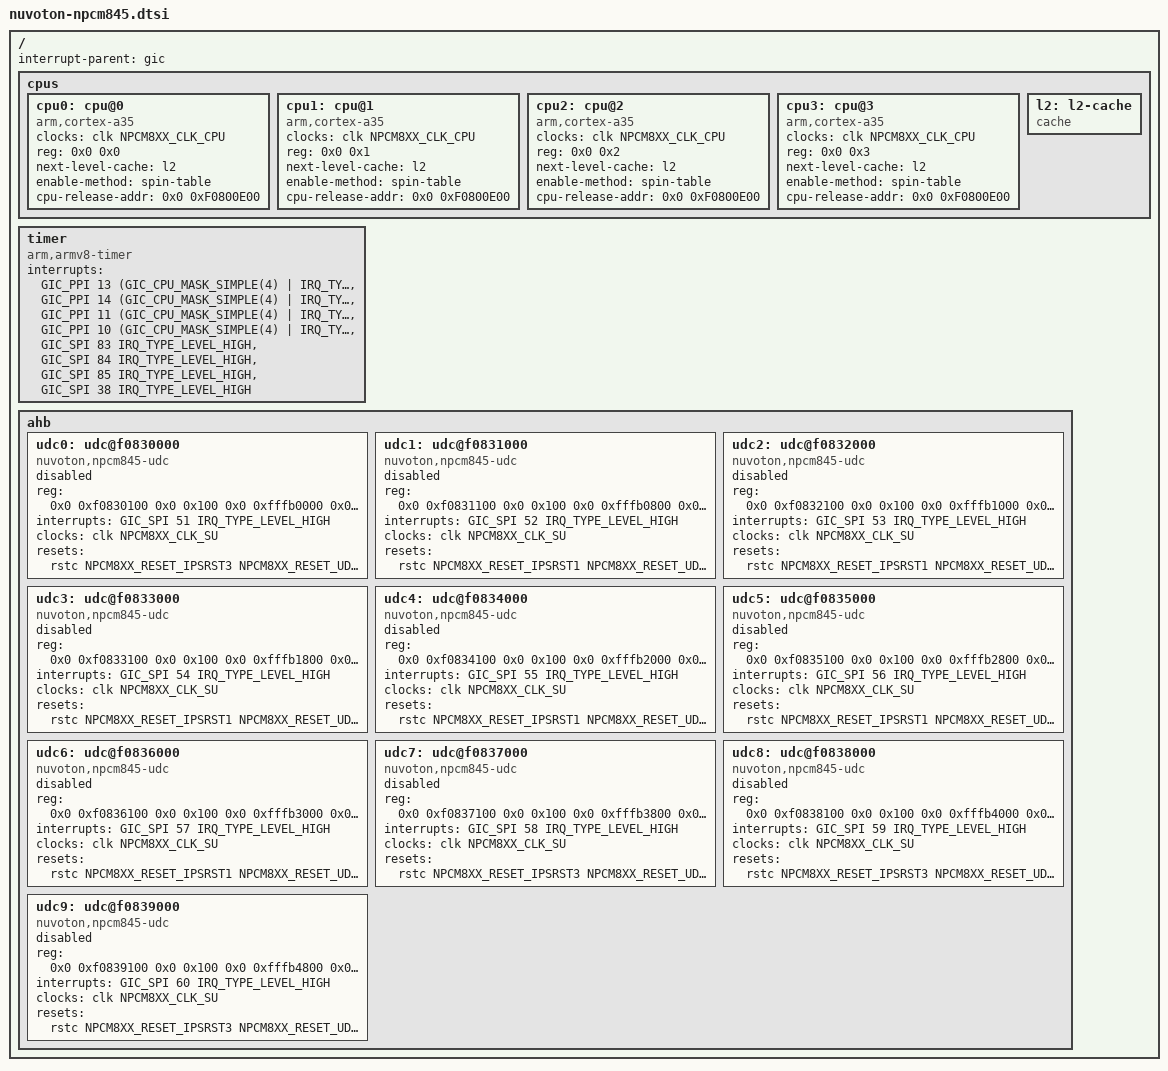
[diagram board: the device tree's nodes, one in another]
// SPDX-License-Identifier: GPL-2.0
// Copyright (c) 2018 Nuvoton Technology tomer.maimon@nuvoton.com
// Copyright 2018 Google, Inc.

#include "nuvoton-common-npcm8xx.dtsi"

/ {
	#address-cells = <2>;
	#size-cells = <2>;
	interrupt-parent = <&gic>;

	cpus {
		#address-cells = <2>;
		#size-cells = <0>;

		cpu0: cpu@0 {
			device_type = "cpu";
			compatible = "arm,cortex-a35";
			clocks = <&clk NPCM8XX_CLK_CPU>;
			reg = <0x0 0x0>;
			next-level-cache = <&l2>;
			enable-method = "spin-table";
			cpu-release-addr = <0x0 0xF0800E00>;
		};

		cpu1: cpu@1 {
			device_type = "cpu";
			compatible = "arm,cortex-a35";
			clocks = <&clk NPCM8XX_CLK_CPU>;
			reg = <0x0 0x1>;
			next-level-cache = <&l2>;
			enable-method = "spin-table";
			cpu-release-addr = <0x0 0xF0800E00>;
		};

		cpu2: cpu@2 {
			device_type = "cpu";
			compatible = "arm,cortex-a35";
			clocks = <&clk NPCM8XX_CLK_CPU>;
			reg = <0x0 0x2>;
			next-level-cache = <&l2>;
			enable-method = "spin-table";
			cpu-release-addr = <0x0 0xF0800E00>;
		};

		cpu3: cpu@3 {
			device_type = "cpu";
			compatible = "arm,cortex-a35";
			clocks = <&clk NPCM8XX_CLK_CPU>;
			reg = <0x0 0x3>;
			next-level-cache = <&l2>;
			enable-method = "spin-table";
			cpu-release-addr = <0x0 0xF0800E00>;
		};

		l2: l2-cache {
			compatible = "cache";
		};
	};

	timer {
		compatible = "arm,armv8-timer";
		interrupts = <GIC_PPI 13 (GIC_CPU_MASK_SIMPLE(4) | IRQ_TYPE_LEVEL_LOW)>,
			     <GIC_PPI 14 (GIC_CPU_MASK_SIMPLE(4) | IRQ_TYPE_LEVEL_LOW)>,
			     <GIC_PPI 11 (GIC_CPU_MASK_SIMPLE(4) | IRQ_TYPE_LEVEL_LOW)>,
			     <GIC_PPI 10 (GIC_CPU_MASK_SIMPLE(4) | IRQ_TYPE_LEVEL_LOW)>,
			     <GIC_SPI 83 IRQ_TYPE_LEVEL_HIGH>,
			     <GIC_SPI 84 IRQ_TYPE_LEVEL_HIGH>,
			     <GIC_SPI 85 IRQ_TYPE_LEVEL_HIGH>,
			     <GIC_SPI 38 IRQ_TYPE_LEVEL_HIGH>;
	};

	ahb {
		udc0:udc@f0830000 {
			compatible = "nuvoton,npcm845-udc";
			reg = <0x0 0xf0830100 0x0 0x100
			       0x0 0xfffb0000 0x0 0x800>;
			interrupts = <GIC_SPI 51 IRQ_TYPE_LEVEL_HIGH>;
			clocks = <&clk NPCM8XX_CLK_SU>;
			clock-names = "clk_usb_bridge";
			resets = <&rstc NPCM8XX_RESET_IPSRST3 NPCM8XX_RESET_UDC0>;
			status = "disable";
		};

		udc1:udc@f0831000 {
			compatible = "nuvoton,npcm845-udc";
			reg = <0x0 0xf0831100 0x0 0x100
			       0x0 0xfffb0800 0x0 0x800>;
			interrupts = <GIC_SPI 52 IRQ_TYPE_LEVEL_HIGH>;
			clocks = <&clk NPCM8XX_CLK_SU>;
			clock-names = "clk_usb_bridge";
			resets = <&rstc NPCM8XX_RESET_IPSRST1 NPCM8XX_RESET_UDC1>;
			status = "disable";
		};

		udc2:udc@f0832000 {
			compatible = "nuvoton,npcm845-udc";
			reg = <0x0 0xf0832100 0x0 0x100
			       0x0 0xfffb1000 0x0 0x800>;
			interrupts = <GIC_SPI 53 IRQ_TYPE_LEVEL_HIGH>;
			clocks = <&clk NPCM8XX_CLK_SU>;
			clock-names = "clk_usb_bridge";
			resets = <&rstc NPCM8XX_RESET_IPSRST1 NPCM8XX_RESET_UDC2>;
			status = "disable";
		};

		udc3:udc@f0833000 {
			compatible = "nuvoton,npcm845-udc";
			reg = <0x0 0xf0833100 0x0 0x100
			       0x0 0xfffb1800 0x0 0x800>;
			interrupts = <GIC_SPI 54 IRQ_TYPE_LEVEL_HIGH>;
			clocks = <&clk NPCM8XX_CLK_SU>;
			clock-names = "clk_usb_bridge";
			resets = <&rstc NPCM8XX_RESET_IPSRST1 NPCM8XX_RESET_UDC3>;
			status = "disable";
		};

		udc4:udc@f0834000 {
			compatible = "nuvoton,npcm845-udc";
			reg = <0x0 0xf0834100 0x0 0x100
			       0x0 0xfffb2000 0x0 0x800>;
			interrupts = <GIC_SPI 55 IRQ_TYPE_LEVEL_HIGH>;
			clocks = <&clk NPCM8XX_CLK_SU>;
			clock-names = "clk_usb_bridge";
			resets = <&rstc NPCM8XX_RESET_IPSRST1 NPCM8XX_RESET_UDC4>;
			status = "disable";
		};

		udc5:udc@f0835000 {
			compatible = "nuvoton,npcm845-udc";
			reg = <0x0 0xf0835100 0x0 0x100
			       0x0 0xfffb2800 0x0 0x800>;
			interrupts = <GIC_SPI 56 IRQ_TYPE_LEVEL_HIGH>;
			clocks = <&clk NPCM8XX_CLK_SU>;
			clock-names = "clk_usb_bridge";
			resets = <&rstc NPCM8XX_RESET_IPSRST1 NPCM8XX_RESET_UDC5>;
			status = "disable";
		};

		udc6:udc@f0836000 {
			compatible = "nuvoton,npcm845-udc";
			reg = <0x0 0xf0836100 0x0 0x100
			       0x0 0xfffb3000 0x0 0x800>;
			interrupts = <GIC_SPI 57 IRQ_TYPE_LEVEL_HIGH>;
			clocks = <&clk NPCM8XX_CLK_SU>;
			clock-names = "clk_usb_bridge";
			resets = <&rstc NPCM8XX_RESET_IPSRST1 NPCM8XX_RESET_UDC6>;
			status = "disable";
		};

		udc7:udc@f0837000 {
			compatible = "nuvoton,npcm845-udc";
			reg = <0x0 0xf0837100 0x0 0x100
			       0x0 0xfffb3800 0x0 0x800>;
			interrupts = <GIC_SPI 58 IRQ_TYPE_LEVEL_HIGH>;
			clocks = <&clk NPCM8XX_CLK_SU>;
			clock-names = "clk_usb_bridge";
			resets = <&rstc NPCM8XX_RESET_IPSRST3 NPCM8XX_RESET_UDC7>;
			status = "disable";
		};

		udc8:udc@f0838000 {
			compatible = "nuvoton,npcm845-udc";
			reg = <0x0 0xf0838100 0x0 0x100
			       0x0 0xfffb4000 0x0 0x800>;
			interrupts = <GIC_SPI 59 IRQ_TYPE_LEVEL_HIGH>;
			clocks = <&clk NPCM8XX_CLK_SU>;
			clock-names = "clk_usb_bridge";
			resets = <&rstc NPCM8XX_RESET_IPSRST3 NPCM8XX_RESET_UDC8>;
			status = "disable";
		};

		udc9:udc@f0839000 {
			compatible = "nuvoton,npcm845-udc";
			reg = <0x0 0xf0839100 0x0 0x100
			       0x0 0xfffb4800 0x0 0x800>;
			interrupts = <GIC_SPI 60 IRQ_TYPE_LEVEL_HIGH>;
			clocks = <&clk NPCM8XX_CLK_SU>;
			clock-names = "clk_usb_bridge";
			resets = <&rstc NPCM8XX_RESET_IPSRST3 NPCM8XX_RESET_UDC9>;
			status = "disable";
		};
	};
};
